# SIM3U164_B register map
File version: 1
CPU: 
Registers are 32-bit, read-write, reset 0x0 unless marked. A register's access mark holds for its fields unless they carry their own. Offsets are from the block's base; [hi:lo] are bit positions; <NAME> marks a mode.

## VREF_0
Base 0x40039010
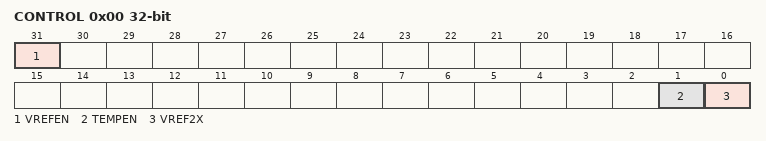
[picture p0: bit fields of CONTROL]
0x00 CONTROL — Voltage Reference Control
  [31] VREFEN — Voltage Reference Enable.
    0=DISABLED (Disable the Voltage Reference.); 1=ENABLED (Enable the Voltage Reference.)
  [1] TEMPEN — Temperature Sensor Enable.
    0=DISABLED (Disable the temperature sensor.); 1=ENABLED (Enable the temperature sensor.)
  [0] VREF2X — Voltage Reference Doubler.
    0=DISABLED (VREF output is nominally 1.2 V); 1=ENABLED (VREF output is nominally 2.4 V)

## VREG_0
Base 0x40040000
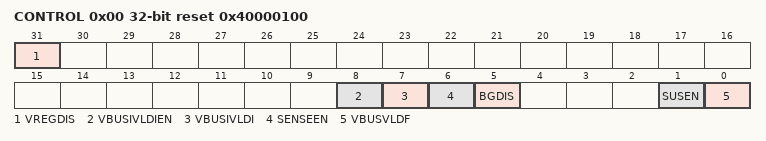
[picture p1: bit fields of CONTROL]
0x00 CONTROL reset 0x40000100 — Module Control
  [31] VREGDIS — Voltage Regulator Disable.
    0=INACTIVE (Enable the voltage regulator.); 1=ACTIVE (Disable the voltage regulator.)
  [8] VBUSIVLDIEN — VBUS Invalid Interrupt Enable.
    0=DISABLED (Disable the VBUS invalid interrupt.); 1=ENABLED (Enable the VBUS invalid interrupt.)
  [7] VBUSIVLDI — VBUS Invalid Interrupt Flag.
    0=NOT_SET (The voltage on the VBUS pin has not dropped below the valid threshold.); 1=SET (The voltage on the VBUS pin dropped below the valid threshold since the last time this bit was cleared.)
  [6] SENSEEN — VREGIN Sense Enable.
    0=DISABLED (Disable VREGIN voltage sensing.); 1=ENABLED (Enable VREGIN voltage sensing.)
  [5] BGDIS — Band Gap Disable.
    0=INACTIVE (Enable the voltage regulator band gap.); 1=ACTIVE (Disable the voltage regulator band gap.)
  [1] SUSEN — Voltage Regulator Suspend Enable.
    0=DISABLED (Disable regulator suspend mode.); 1=ENABLED (Enable regulator suspend mode.)
  [0] VBUSVLDF ro — VBUS Valid Flag.
    0=NOT_SET (The current voltage on the VBUS pin is below the valid threshold.); 1=SET (The current voltage on the VBUS pin is above the valid threshold.)

## LDO_0
Base 0x40039000
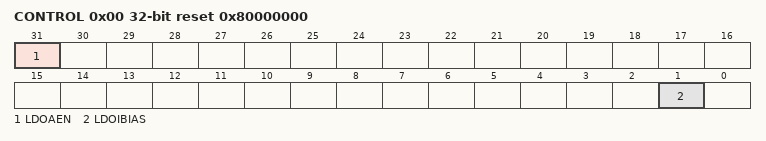
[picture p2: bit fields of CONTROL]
0x00 CONTROL reset 0x80000000
  [31] LDOAEN — LDO Analog Enable.
    0=DISABLE (LDO0 analog output disabled.); 1=ENABLE (LDO0 analog output enabled.)
  [1] LDOIBIAS — LDO Bias Current Selection.
    0=HIGHBIAS (Select high bias.); 1=LOWBIAS (Select low bias (AHB frequency <= 2.5 MHz).)

## WDTIMER_0
Base 0x40030000
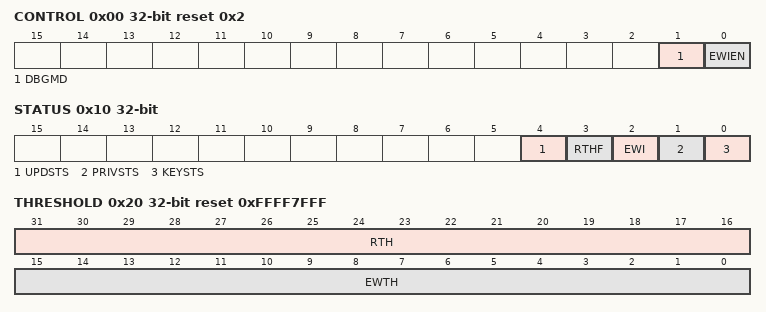
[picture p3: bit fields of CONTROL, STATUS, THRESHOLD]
0x00 CONTROL reset 0x2 — Module Control
  [1] DBGMD — Watchdog Timer Debug Mode.
    0=RUN (The WDTIMER module will continue to operate while the core is halted in debug mode.); 1=HALT (A debug breakpoint will cause the WDTIMER module to halt.)
  [0] EWIEN — Early Warning Interrupt Enable.
    0=DISABLED (Disable the early warning interrupt (EWI).); 1=ENABLED (Enable the early warning interrupt (EWI).)
0x10 STATUS — Module Status
  [4] UPDSTS ro — Watchdog Timer Threshold Update Status.
    0=IDLE (An update completed or is not pending. The EWTH and RTH fields can be written.); 1=UPDATING (An update of the threshold register is occurring. The EWTH and RTH fields should not be modified until hardware clears UPDSTS to 0.)
  [3] RTHF ro — Reset Threshold Flag.
    0=LT (The counter is currently less than the reset threshold (RTH) value.); 1=GTE (The counter is currently greater than or equal to the reset threshold (RTH) value.)
  [2] EWI — Early Warning Interrupt Flag.
    0=NOT_SET (Read: An early warning match did not occur. Write: Clear the early warning interrupt.); 1=SET (Read: An early warning match occurred and the interrupt is pending. Write: Force a watchdog timer early warning interrupt to occur.)
  [1] PRIVSTS ro — Register Access Status.
    0=READ_ONLY (The watchdog timer registers are currently read-only.); 1=READ_WRITE (A write transaction can be performed on the module registers.)
  [0] KEYSTS ro — Key Status.
    0=IDLE (No keys have been processed by the interface.); 1=READY (The attention key has been received and the module is awaiting a command.)
0x20 THRESHOLD reset 0xFFFF7FFF — Threshold Values
  [31:16] RTH — Reset Threshold.
  [15:0] EWTH — Early Warning Threshold.
0x30 WDTKEY — Module Key
  [7:0] KEY wo — Watchdog Timer Key.
    165=ATTN (Attention key to start the command sequence.); 204=RESET (Reset the watchdog timer.); 221=DISABLE (Disable the watchdog timer.); 238=START (Start the watchdog timer.); 241=WRITE (Allow one write access to the module registers.); 255=LOCK (Lock the module from any other writes until the next system reset.)
